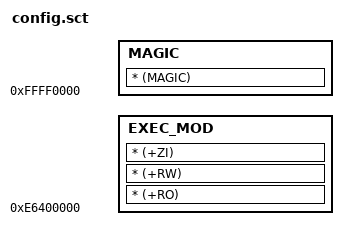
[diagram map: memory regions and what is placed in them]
;/*
;*********************************************************************************************************************
;*                                                    ePDK
;*                                    the Easy Portable/Player Develop Kits
;*
;*                                   (c) Copyright 2007-2009, Steven.ZGJ.China
;*                                             All Rights Reserved
;*
;* Moudle  : scatter file
;* File    : config.sct
;*
;* By      : Steven
;* Version : v1.0
;* Date    : 2008-9-17 11:59:06
;*********************************************************************************************************************
;*/

LO_FIRST 0xe6400000 0x50000
{
    EXEC_MOD  0xe6400000                           ;// 内核代码和数据区,其中30是用于存放KRNL_HEAD代码
    {
        * (+RO) 
        * (+RW) 
        * (+ZI)
    }        
    MAGIC  0xFFFF0000
    {
        * (MAGIC)
    }
}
